# STC32G144K246 register map
Vendor: STC; File version: 2.0
Registers are 8-bit, read-write, no defined reset value unless marked. A register's access mark holds for its fields unless they carry their own. Offsets are from the block's base; [hi:lo] are bit positions.

## UART4 — USART4 收发、运行模式与超时
Base 0x007EFD7D
0x00 UR4TOSR ro — 串口4接收超时状态寄存器
  [0] UR4TOIF — 串口4 超时中断请求标志位。标志位需要软件向UR4CTOIF 位写“1”清零
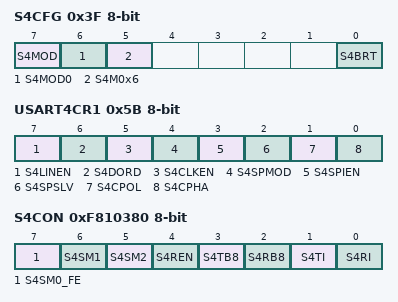
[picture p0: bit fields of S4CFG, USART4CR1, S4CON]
0x3F S4CFG — 串口4配置寄存器
  [7] S4MOD — 串口4 波特率控制位
    0=SYSclk波特率=𝟔𝟒; 1=SYSclk波特率=𝟑𝟐
  [6] S4MOD0 — 帧错误检测控制位
    0=无帧错检测功能; 1=使能帧错误检测功能。此时S4CON 的S4SM0/FE 为FE 功能，即为帧错误检测标志位。
  [5] S4M0x6 — 串口4 模式0 的通讯速度控制
    0=串口4 模式0 的波特率不加倍，固定为Fosc/12; 1=串口4 模式0 的波特率6 倍速，即固定为Fosc/12*6 ＝ Fosc/2
  [0] S4BRT — 串口4 波特率发生器选择位
    0=选择定时器2 作为波特率发生器（默认值）; 1=选择定时器4 作为波特率发生器
0x5B USART4CR1 — 串口4控制寄存器1
  [7] S4LINEN — LIN 模式使能位
    0=禁止LIN 模式; 1=使能LIN 模式
  [6] S4DORD — SPI 模式数据位发送/接收的顺序
    0=先发送/接收数据的高位（MSB）; 1=先发送/接收数据的低位（LSB）
  [5] S4CLKEN — SmartCard 模式时钟输出控制位
    0=禁止时钟输出; 1=使能时钟输出
  [4] S4SPMOD — SPI 模式使能位
    0=禁止SPI 模式; 1=使能SPI 模式
  [3] S4SPIEN — SPI 使能位
    0=禁止SPI 功能; 1=使能SPI 功能
  [2] S4SPSLV — SPI 从机模式使能位
    0=SPI 为主机模式; 1=SPI 为从机模式
  [1] S4CPOL — SPI 时钟极性控制
    0=SCLK 空闲时为低电平，SCLK 的前时钟沿为上升沿，后时钟沿为下降沿; 1=SCLK 空闲时为高电平，SCLK 的前时钟沿为下降沿，后时钟沿为上升沿
  [0] S4CPHA — SPI 时钟相位控制
    0=数据SS 管脚为低电平驱动第一位数据并在SCLK 的后时钟沿改变数据，前时钟沿采样数据; 1=数据在SCLK 的前时钟沿驱动，后时钟沿采样
0xF810380 S4CON — 串口4控制寄存器
  [7] S4SM0_FE — 当S4CFG寄存器中的S4MOD0位为1时，该位为帧错误检测标志位。当串口4在接收过程中检
  [6] S4SM1 — 尚未自动匹配到此字段的独立说明；请查看下方章节说明。
  [5] S4SM2 — 允许模式2 或模式3 多机通信控制位。当串口4 使用模式2 或模式3 时，如果S4SM2 位为1 且 S4REN 位为1，则接收机处于地址帧筛选状态。此时可以利用接收到的第9 位（即S4RB8）来筛 选地址帧，若S4RB8=1，说明该帧是地址帧，地址信息可以进入S4BUF，并使S4RI 为1，进而
  [4] S4REN — 允许/禁止串口接收控制位
    0=禁止串口接收数据; 1=允许串口接收数据
  [3] S4TB8 — 当串口4 使用模式2 或模式3 时，S4TB8 为要发送的第9 位数据，按需要由软件置位或清0。 在模式0 和模式1 中，该位不用。
  [2] S4RB8 — 当串口4 使用模式2 或模式3 时，S4RB8 为接收到的第9 位数据，一般用作校验位或者地址帧 /数据帧标志位。在模式0 和模式1 中，该位不用。
  [1] S4TI — 串口4发送完成中断请求标志。需要软件清零。
  [0] S4RI — 串口4 接收完成中断请求标志。需要软件清零。

## UART5 — USART5 收发、运行模式与超时
Base 0x007EF740
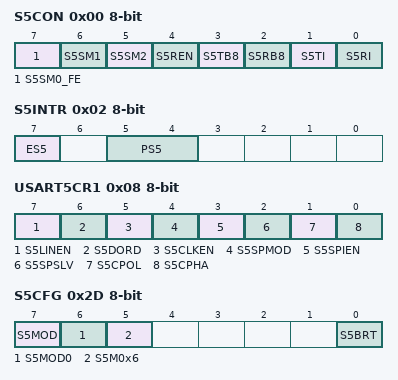
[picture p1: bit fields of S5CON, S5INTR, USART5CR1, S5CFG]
0x00 S5CON — 串口5控制寄存器
  [7] S5SM0_FE — 当S5CFG寄存器中的S5MOD0位为1时，该位为帧错误检测标志位。当串口5在接收过程中检
  [6] S5SM1 — 尚未自动匹配到此字段的独立说明；请查看下方章节说明。
  [5] S5SM2 — 允许模式2 或模式3 多机通信控制位。当串口5 使用模式2 或模式3 时，如果S5SM2 位为1 且 S5REN 位为1，则接收机处于地址帧筛选状态。此时可以利用接收到的第9 位（即S5RB8）来筛 选地址帧，若S5RB8=1，说明该帧是地址帧，地址信息可以进入S5BUF，并使S5RI 为1，进而
  [4] S5REN — 允许/禁止串口接收控制位
    0=禁止串口接收数据; 1=允许串口接收数据
  [3] S5TB8 — 当串口5 使用模式2 或模式3 时，S5TB8 为要发送的第9 位数据，按需要由软件置位或清0。 在模式0 和模式1 中，该位不用。
  [2] S5RB8 — 当串口5 使用模式2 或模式3 时，S5RB8 为接收到的第9 位数据，一般用作校验位或者地址帧 /数据帧标志位。在模式0 和模式1 中，该位不用。
  [1] S5TI — 串口5发送完成中断请求标志。需要软件清零。
  [0] S5RI — 串口5接收完成中断请求标志。需要软件清零。
0x02 S5INTR — 串口5中断寄存器
  [7] ES5 — 串口5 中断使能控制位
    0=禁止串口5 中断; 1=允许串口5 中断
  [5:4] PS5 — 串口5 中断优先级控制位
    0=串口5 中断优先级为0 级（最低级）; 1=串口5 中断优先级为1 级（较低级）; 2=串口5 中断优先级为2 级（较高级）; 3=串口5 中断优先级为3 级（最高级）
0x05 UR5TOSR ro — 串口5接收超时状态寄存器
  [0] UR5TOIF — 串口5 超时中断请求标志位。标志位需要软件向UR5CTOIF 位写“1”清零
0x08 USART5CR1 — 串口5控制寄存器1
  [7] S5LINEN — LIN 模式使能位
    0=禁止LIN 模式; 1=使能LIN 模式
  [6] S5DORD — SPI 模式数据位发送/接收的顺序
    0=先发送/接收数据的高位（MSB）; 1=先发送/接收数据的低位（LSB）
  [5] S5CLKEN — SmartCard 模式时钟输出控制位
    0=禁止时钟输出; 1=使能时钟输出
  [4] S5SPMOD — SPI 模式使能位
    0=禁止SPI 模式; 1=使能SPI 模式
  [3] S5SPIEN — SPI 使能位
    0=禁止SPI 功能; 1=使能SPI 功能
  [2] S5SPSLV — SPI 从机模式使能位
    0=SPI 为主机模式; 1=SPI 为从机模式
  [1] S5CPOL — SPI 时钟极性控制
    0=SCLK 空闲时为低电平，SCLK 的前时钟沿为上升沿，后时钟沿为下降沿; 1=SCLK 空闲时为高电平，SCLK 的前时钟沿为下降沿，后时钟沿为上升沿
  [0] S5CPHA — SPI 时钟相位控制
    0=数据SS 管脚为低电平驱动第一位数据并在SCLK 的后时钟沿改变数据，前时钟沿采样数据; 1=数据在SCLK 的前时钟沿驱动，后时钟沿采样
0x2D S5CFG — 串口5配置寄存器
  [7] S5MOD — 串口5 波特率控制位
    0=SYSclk波特率=𝟔𝟒; 1=SYSclk波特率=𝟑𝟐
  [6] S5MOD0 — 帧错误检测控制位
    0=无帧错检测功能; 1=使能帧错误检测功能。此时S5CON 的S5SM0/FE 为FE 功能，即为帧错误检测标志位。
  [5] S5M0x6 — 串口5 模式0 的通讯速度控制
    0=串口5 模式0 的波特率不加倍，固定为Fosc/12; 1=串口5 模式0 的波特率6 倍速，即固定为Fosc/12*6 ＝ Fosc/2
  [0] S5BRT — 串口5 波特率发生器选择位
    0=选择定时器2 作为波特率发生器（默认值）; 1=选择定时器5 作为波特率发生器

## UART6 — USART6 收发、运行模式与超时
Base 0x007EF770
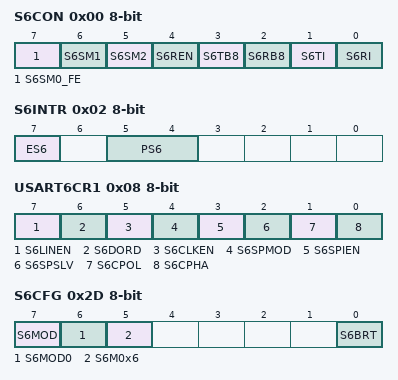
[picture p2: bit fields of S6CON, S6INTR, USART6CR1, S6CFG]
0x00 S6CON — 串口6控制寄存器
  [7] S6SM0_FE — 当S6CFG寄存器中的S6MOD0位为1时，该位为帧错误检测标志位。当串口6在接收过程中检
  [6] S6SM1 — 尚未自动匹配到此字段的独立说明；请查看下方章节说明。
  [5] S6SM2 — 允许模式2 或模式3 多机通信控制位。当串口6 使用模式2 或模式3 时，如果S6SM2 位为1 且 S6REN 位为1，则接收机处于地址帧筛选状态。此时可以利用接收到的第9 位（即S6RB8）来筛 选地址帧，若S6RB8=1，说明该帧是地址帧，地址信息可以进入S6BUF，并使S6RI 为1，进而
  [4] S6REN — 允许/禁止串口接收控制位
    0=禁止串口接收数据; 1=允许串口接收数据
  [3] S6TB8 — 当串口6 使用模式2 或模式3 时，S6TB8 为要发送的第9 位数据，按需要由软件置位或清0。 在模式0 和模式1 中，该位不用。
  [2] S6RB8 — 当串口6 使用模式2 或模式3 时，S6RB8 为接收到的第9 位数据，一般用作校验位或者地址帧 /数据帧标志位。在模式0 和模式1 中，该位不用。
  [1] S6TI — 串口6发送完成中断请求标志。需要软件清零。
  [0] S6RI — 串口6接收完成中断请求标志。需要软件清零。
0x02 S6INTR — 串口6中断寄存器
  [7] ES6 — 串口6 中断使能控制位
    0=禁止串口6 中断; 1=允许串口6 中断
  [5:4] PS6 — 串口6 中断优先级控制位
    0=串口6 中断优先级为0 级（最低级）; 1=串口6 中断优先级为1 级（较低级）; 2=串口6 中断优先级为2 级（较高级）; 3=串口6 中断优先级为3 级（最高级）
0x05 UR6TOSR ro — 串口6接收超时状态寄存器
  [0] UR6TOIF — 串口6 超时中断请求标志位。标志位需要软件向UR6CTOIF 位写“1”清零
0x08 USART6CR1 — 串口6控制寄存器1
  [7] S6LINEN — LIN 模式使能位
    0=禁止LIN 模式; 1=使能LIN 模式
  [6] S6DORD — SPI 模式数据位发送/接收的顺序
    0=先发送/接收数据的高位（MSB）; 1=先发送/接收数据的低位（LSB）
  [5] S6CLKEN — SmartCard 模式时钟输出控制位
    0=禁止时钟输出; 1=使能时钟输出
  [4] S6SPMOD — SPI 模式使能位
    0=禁止SPI 模式; 1=使能SPI 模式
  [3] S6SPIEN — SPI 使能位
    0=禁止SPI 功能; 1=使能SPI 功能
  [2] S6SPSLV — SPI 从机模式使能位
    0=SPI 为主机模式; 1=SPI 为从机模式
  [1] S6CPOL — SPI 时钟极性控制
    0=SCLK 空闲时为低电平，SCLK 的前时钟沿为上升沿，后时钟沿为下降沿; 1=SCLK 空闲时为高电平，SCLK 的前时钟沿为下降沿，后时钟沿为上升沿
  [0] S6CPHA — SPI 时钟相位控制
    0=数据SS 管脚为低电平驱动第一位数据并在SCLK 的后时钟沿改变数据，前时钟沿采样数据; 1=数据在SCLK 的前时钟沿驱动，后时钟沿采样
0x2D S6CFG — 串口6配置寄存器
  [7] S6MOD — 串口6 波特率控制位
    0=SYSclk波特率=𝟔𝟒; 1=SYSclk波特率=𝟑𝟐
  [6] S6MOD0 — 帧错误检测控制位
    0=无帧错检测功能; 1=使能帧错误检测功能。此时S6CON 的S6SM0/FE 为FE 功能，即为帧错误检测标志位。
  [5] S6M0x6 — 串口6 模式0 的通讯速度控制
    0=串口6 模式0 的波特率不加倍，固定为Fosc/12; 1=串口6 模式0 的波特率6 倍速，即固定为Fosc/12*6 ＝ Fosc/2
  [0] S6BRT — 串口6 波特率发生器选择位
    0=选择定时器2 作为波特率发生器（默认值）; 1=选择定时器6 作为波特率发生器
